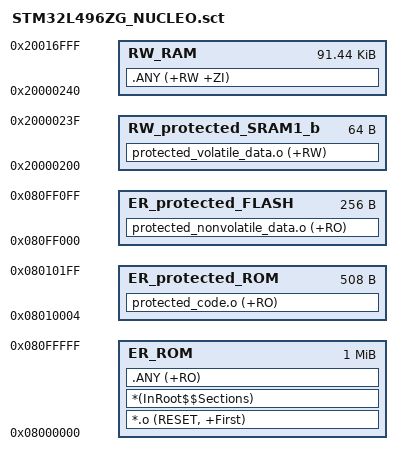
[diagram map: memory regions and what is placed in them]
; *************************************************************
; *** Scatter-Loading Description File generated by uVision ***
; *************************************************************

LR_ROM 0x08000000 0x00100000  {    ; load region size_region
  ER_ROM 0x08000000 0x00100000  {  ; load address = execution address
   *.o (RESET, +First)
   *(InRoot$$Sections)
   .ANY (+RO)
  }
  RW_RAM 0x20000240 0x00016DC0  {  ; RW data
   .ANY (+RW +ZI)
  }
 
; /****************************************************************************/
; /*                                                                          */
; /*     SRAM1_a: used to locate executable code in volatile data segment     */
; /*                  protected non-volatile data segment                     */
; /*               no code is located in this region                                                           */
; /****************************************************************************/
;RW_protected_SRAM1_a 0x20000004 0x00001FC {    
;}
;/******************************************************************************/  
;/*         place volatile data in SRAM1 area (more specifically in            */
;/*             SRAM1_b sub-region) to be protected by FIREWALL                */
;/******************************************************************************/ 
RW_protected_SRAM1_b 0x20000200 0x0000040 { 
protected_volatile_data.o (+RW)   
}
}


; /****************************************************************************/
; /*                                                                          */
; /*          LR_ROM1: used to locate code in protected code segment          */
; /*                                                                          */
; /****************************************************************************/
; /* Note that the protected code segment doesn't exactly start at the 
;    starting address used to configure de Firewall.
;    This allows to locate the function used to open the Firewall at the
;    correct address to obey the call gate sequence */
LR_protected_ROM 0x08010004 0x00001FC {
  ER_protected_ROM 0x08010004 0x00001FC  {  ; load address = execution address
    protected_code.o (+RO)
	
  }
}

; /****************************************************************************/
; /*                                                                          */
; /*              LR_FLASH: used to locate data in protected                   */
; /*                    non-volatile data segment                             */
; /*                                                                          */
; /*****************************************************************************/
LR_protected_FLASH 0x080FF000 0x0000100 {
  ER_protected_FLASH 0x080FF000 0x0000100  {  
    protected_nonvolatile_data.o (+RO)
	
  }
}

